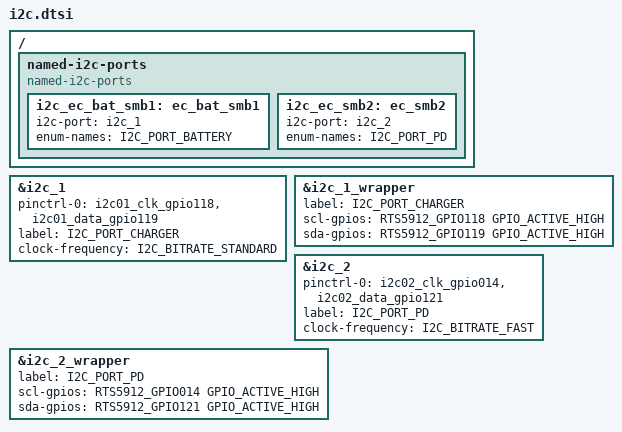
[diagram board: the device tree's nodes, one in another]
/* Copyright 2026 The ChromiumOS Authors
 * Use of this source code is governed by a BSD-style license that can be
 * found in the LICENSE file.
 */

/ {
	named-i2c-ports {
		compatible = "named-i2c-ports";

		/* EC_BAT_SMB1 */
		i2c_ec_bat_smb1: ec_bat_smb1 {
			i2c-port = <&i2c_1>;
			enum-names = "I2C_PORT_BATTERY";
		};
		/* EC_SMB2 */
		i2c_ec_smb2: ec_smb2 {
			i2c-port = <&i2c_2>;
			enum-names = "I2C_PORT_PD";
		};
	};
};

&i2c_1 {
	pinctrl-0 = <&i2c01_clk_gpio118
		     &i2c01_data_gpio119>;
	pinctrl-names = "default";

	label = "I2C_PORT_CHARGER";
	clock-frequency = <I2C_BITRATE_STANDARD>;
	status = "okay";
};

&i2c_1_wrapper {
	label = "I2C_BATTERY";
	label = "I2C_PORT_CHARGER";
	status = "okay";
	scl-gpios = <RTS5912_GPIO118 GPIO_ACTIVE_HIGH>;
	sda-gpios = <RTS5912_GPIO119 GPIO_ACTIVE_HIGH>;
};

&i2c_2 {
	pinctrl-0 = <&i2c02_clk_gpio014
		     &i2c02_data_gpio121>;
	pinctrl-names = "default";

	label = "I2C_PORT_PD";
	clock-frequency = <I2C_BITRATE_FAST>;
	status = "okay";
};

&i2c_2_wrapper {
	label = "I2C_PORT_PD";
	status = "okay";
	scl-gpios = <RTS5912_GPIO014 GPIO_ACTIVE_HIGH>;
	sda-gpios = <RTS5912_GPIO121 GPIO_ACTIVE_HIGH>;
};
